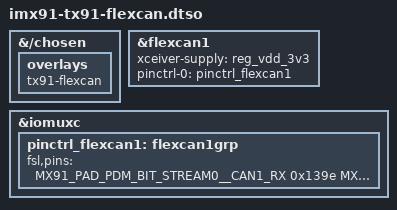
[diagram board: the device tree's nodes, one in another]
// SPDX-License-Identifier: (GPL-2.0 OR MIT)
/*
 * Copyright 2023 Lothar Waßmann <LW@KARO-electronics.de>
 *
 */

/dts-v1/;
/plugin/;

#include "imx91-pinfunc.h"

&{/chosen} {
	overlays {
		tx91-flexcan;
	};
};

&flexcan1 {
	xceiver-supply = <&reg_vdd_3v3>;
	pinctrl-names = "default";
	pinctrl-0 = <&pinctrl_flexcan1>;
	status = "okay";
};

&iomuxc {
	pinctrl_flexcan1: flexcan1grp {
		fsl,pins = <
			MX91_PAD_PDM_BIT_STREAM0__CAN1_RX	0x139e
			MX91_PAD_PDM_CLK__CAN1_TX		0x139e
		>;
	};
};
